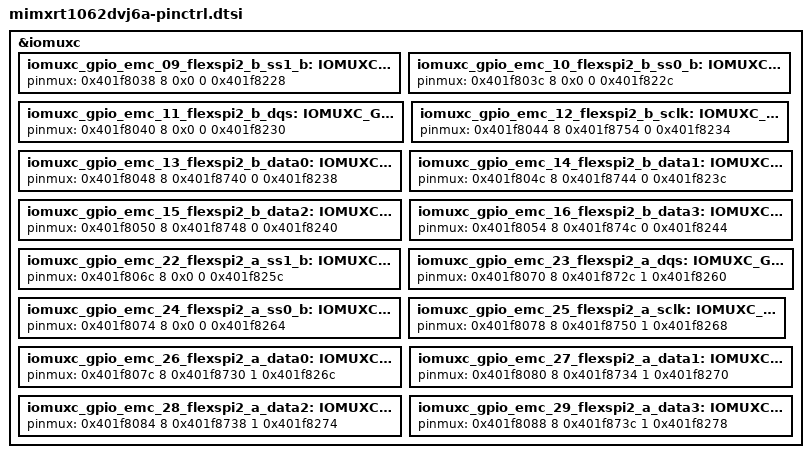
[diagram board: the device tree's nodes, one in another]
/*
 * Copyright (c) 2022, NXP
 * SPDX-License-Identifier: Apache-2.0
 *
 * Note: File generated by rt_cfg_utils.py
 * from configuration data for MIMXRT1062DVJ6A
 */

/*
 * Delta-deduplicated by dedup_pinctrl.py:
 * based on mimxrt1064dvj6a-pinctrl.dtsi with this part's differences applied
 * below (0 removed, 0 changed,
 * 16 added). Regenerate with dedup_pinctrl.py;
 * do not edit by hand.
 * target-hash: 304d2df1a5f7ddd6
 */

#include "mimxrt1064dvj6a-pinctrl.dtsi"

&iomuxc {
	/omit-if-no-ref/ iomuxc_gpio_emc_09_flexspi2_b_ss1_b: IOMUXC_GPIO_EMC_09_FLEXSPI2_B_SS1_B {
		pinmux = <0x401f8038 8 0x0 0 0x401f8228>;
	};
	/omit-if-no-ref/ iomuxc_gpio_emc_10_flexspi2_b_ss0_b: IOMUXC_GPIO_EMC_10_FLEXSPI2_B_SS0_B {
		pinmux = <0x401f803c 8 0x0 0 0x401f822c>;
	};
	/omit-if-no-ref/ iomuxc_gpio_emc_11_flexspi2_b_dqs: IOMUXC_GPIO_EMC_11_FLEXSPI2_B_DQS {
		pinmux = <0x401f8040 8 0x0 0 0x401f8230>;
	};
	/omit-if-no-ref/ iomuxc_gpio_emc_12_flexspi2_b_sclk: IOMUXC_GPIO_EMC_12_FLEXSPI2_B_SCLK {
		pinmux = <0x401f8044 8 0x401f8754 0 0x401f8234>;
	};
	/omit-if-no-ref/ iomuxc_gpio_emc_13_flexspi2_b_data0: IOMUXC_GPIO_EMC_13_FLEXSPI2_B_DATA0 {
		pinmux = <0x401f8048 8 0x401f8740 0 0x401f8238>;
	};
	/omit-if-no-ref/ iomuxc_gpio_emc_14_flexspi2_b_data1: IOMUXC_GPIO_EMC_14_FLEXSPI2_B_DATA1 {
		pinmux = <0x401f804c 8 0x401f8744 0 0x401f823c>;
	};
	/omit-if-no-ref/ iomuxc_gpio_emc_15_flexspi2_b_data2: IOMUXC_GPIO_EMC_15_FLEXSPI2_B_DATA2 {
		pinmux = <0x401f8050 8 0x401f8748 0 0x401f8240>;
	};
	/omit-if-no-ref/ iomuxc_gpio_emc_16_flexspi2_b_data3: IOMUXC_GPIO_EMC_16_FLEXSPI2_B_DATA3 {
		pinmux = <0x401f8054 8 0x401f874c 0 0x401f8244>;
	};
	/omit-if-no-ref/ iomuxc_gpio_emc_22_flexspi2_a_ss1_b: IOMUXC_GPIO_EMC_22_FLEXSPI2_A_SS1_B {
		pinmux = <0x401f806c 8 0x0 0 0x401f825c>;
	};
	/omit-if-no-ref/ iomuxc_gpio_emc_23_flexspi2_a_dqs: IOMUXC_GPIO_EMC_23_FLEXSPI2_A_DQS {
		pinmux = <0x401f8070 8 0x401f872c 1 0x401f8260>;
	};
	/omit-if-no-ref/ iomuxc_gpio_emc_24_flexspi2_a_ss0_b: IOMUXC_GPIO_EMC_24_FLEXSPI2_A_SS0_B {
		pinmux = <0x401f8074 8 0x0 0 0x401f8264>;
	};
	/omit-if-no-ref/ iomuxc_gpio_emc_25_flexspi2_a_sclk: IOMUXC_GPIO_EMC_25_FLEXSPI2_A_SCLK {
		pinmux = <0x401f8078 8 0x401f8750 1 0x401f8268>;
	};
	/omit-if-no-ref/ iomuxc_gpio_emc_26_flexspi2_a_data0: IOMUXC_GPIO_EMC_26_FLEXSPI2_A_DATA0 {
		pinmux = <0x401f807c 8 0x401f8730 1 0x401f826c>;
	};
	/omit-if-no-ref/ iomuxc_gpio_emc_27_flexspi2_a_data1: IOMUXC_GPIO_EMC_27_FLEXSPI2_A_DATA1 {
		pinmux = <0x401f8080 8 0x401f8734 1 0x401f8270>;
	};
	/omit-if-no-ref/ iomuxc_gpio_emc_28_flexspi2_a_data2: IOMUXC_GPIO_EMC_28_FLEXSPI2_A_DATA2 {
		pinmux = <0x401f8084 8 0x401f8738 1 0x401f8274>;
	};
	/omit-if-no-ref/ iomuxc_gpio_emc_29_flexspi2_a_data3: IOMUXC_GPIO_EMC_29_FLEXSPI2_A_DATA3 {
		pinmux = <0x401f8088 8 0x401f873c 1 0x401f8278>;
	};
};
